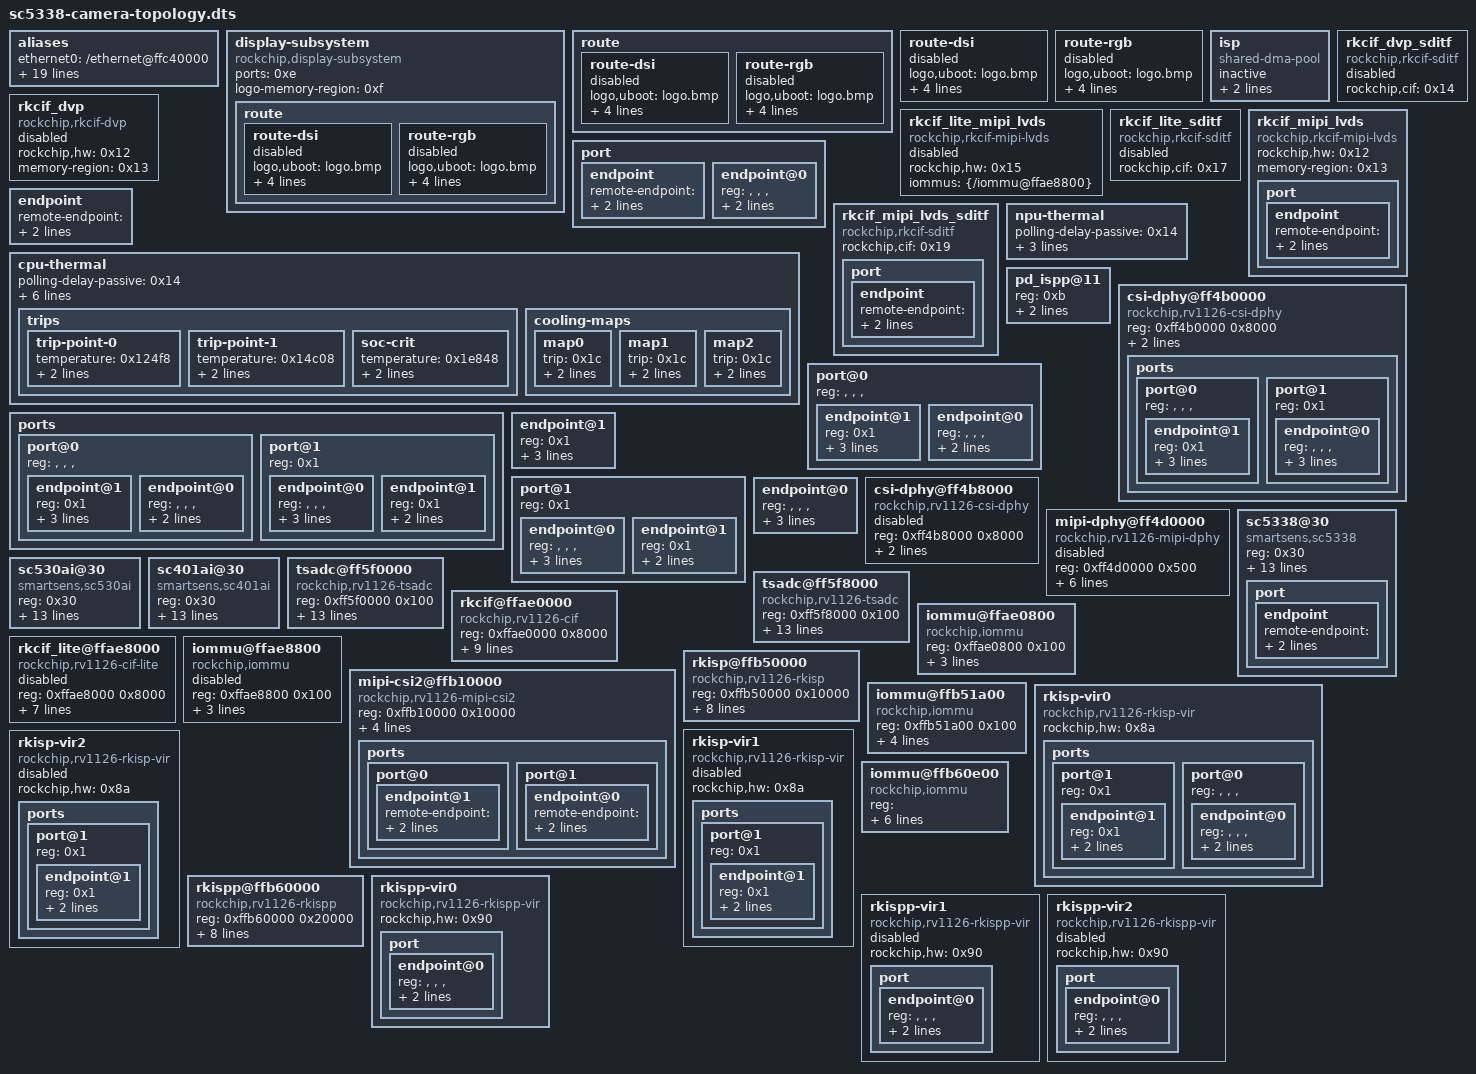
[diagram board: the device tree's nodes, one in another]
/* SC5338 摄像头链路节点摘录 —— 来源 docs/evidence/vendor-kernel.dtb
   DTB 85937 B / md5 2e96cb2dd8321c19425b73490586bb01
   共 441 个节点，命中 72 个摄像头相关节点。
   每个片段前的注释是节点在 DTB 里的完整路径，片段本身可直接抄进目标 DTS。 */

/* /aliases */
aliases {
	ethernet0 = "/ethernet@ffc40000";
	i2c0 = "/i2c@ff3f0000";
	i2c1 = "/i2c@ff510000";
	i2c2 = "/i2c@ff400000";
	i2c3 = "/i2c@ff520000";
	i2c4 = "/i2c@ff530000";
	i2c5 = "/i2c@ff540000";
	mmc0 = "/dwmmc@ffc50000";
	mmc1 = "/dwmmc@ffc70000";
	mmc2 = "/dwmmc@ffc60000";
	serial0 = "/serial@ff560000";
	serial1 = "/serial@ff410000";
	serial2 = "/serial@ff570000";
	serial3 = "/serial@ff580000";
	serial4 = "/serial@ff590000";
	serial5 = "/serial@ff5a0000";
	spi0 = "/spi@ff450000";
	spi1 = "/spi@ff5b0000";
	dphy0 = "/csi-dphy@ff4b0000";
	dphy1 = "/csi-dphy@ff4b8000";
};

/* /display-subsystem */
display-subsystem {
	compatible = "rockchip,display-subsystem";
	ports = <0xe>;
	status = "okay";
	logo-memory-region = <0xf>;
	phandle = <0xc7>;
	route {
		route-dsi {
			status = "disabled";
			logo,uboot = "logo.bmp";
			logo,kernel = "logo_kernel.bmp";
			logo,mode = "center";
			charge_logo,mode = "center";
			connect = <0x10>;
			phandle = <0xc8>;
		};
		route-rgb {
			status = "disabled";
			logo,uboot = "logo.bmp";
			logo,kernel = "logo_kernel.bmp";
			logo,mode = "center";
			charge_logo,mode = "center";
			connect = <0x11>;
			phandle = <0xc9>;
		};
	};
};

/* /display-subsystem/route */
route {
	route-dsi {
		status = "disabled";
		logo,uboot = "logo.bmp";
		logo,kernel = "logo_kernel.bmp";
		logo,mode = "center";
		charge_logo,mode = "center";
		connect = <0x10>;
		phandle = <0xc8>;
	};
	route-rgb {
		status = "disabled";
		logo,uboot = "logo.bmp";
		logo,kernel = "logo_kernel.bmp";
		logo,mode = "center";
		charge_logo,mode = "center";
		connect = <0x11>;
		phandle = <0xc9>;
	};
};

/* /display-subsystem/route/route-dsi */
route-dsi {
	status = "disabled";
	logo,uboot = "logo.bmp";
	logo,kernel = "logo_kernel.bmp";
	logo,mode = "center";
	charge_logo,mode = "center";
	connect = <0x10>;
	phandle = <0xc8>;
};

/* /display-subsystem/route/route-rgb */
route-rgb {
	status = "disabled";
	logo,uboot = "logo.bmp";
	logo,kernel = "logo_kernel.bmp";
	logo,mode = "center";
	charge_logo,mode = "center";
	connect = <0x11>;
	phandle = <0xc9>;
};

/* /reserved-memory/isp */
isp {
	compatible = "shared-dma-pool";
	inactive;
	reusable;
	size = "", "", "", "";
	phandle = <0x13>;
};

/* /rkcif_dvp */
rkcif_dvp {
	compatible = "rockchip,rkcif-dvp";
	rockchip,hw = <0x12>;
	memory-region = <0x13>;
	status = "disabled";
	phandle = <0x14>;
};

/* /rkcif_dvp_sditf */
rkcif_dvp_sditf {
	compatible = "rockchip,rkcif-sditf";
	rockchip,cif = <0x14>;
	status = "disabled";
	phandle = <0xcd>;
};

/* /rkcif_lite_mipi_lvds */
rkcif_lite_mipi_lvds {
	compatible = "rockchip,rkcif-mipi-lvds";
	rockchip,hw = <0x15>;
	iommus = <&{/iommu@ffae8800}>;
	status = "disabled";
	phandle = <0x17>;
};

/* /rkcif_lite_sditf */
rkcif_lite_sditf {
	compatible = "rockchip,rkcif-sditf";
	rockchip,cif = <0x17>;
	status = "disabled";
	phandle = <0xce>;
};

/* /rkcif_mipi_lvds */
rkcif_mipi_lvds {
	compatible = "rockchip,rkcif-mipi-lvds";
	rockchip,hw = <0x12>;
	memory-region = <0x13>;
	status = "okay";
	phandle = <0x19>;
	port {
		endpoint {
			remote-endpoint = <&{/mipi-csi2@ffb10000/ports/port@1/endpoint@0}>;
			data-lanes = <0x1 0x2>;
			phandle = <0x85>;
		};
	};
};

/* /rkcif_mipi_lvds/port */
port {
	endpoint {
		remote-endpoint = <&{/mipi-csi2@ffb10000/ports/port@1/endpoint@0}>;
		data-lanes = <0x1 0x2>;
		phandle = <0x85>;
	};
};

/* /rkcif_mipi_lvds/port/endpoint */
endpoint {
	remote-endpoint = <&{/mipi-csi2@ffb10000/ports/port@1/endpoint@0}>;
	data-lanes = <0x1 0x2>;
	phandle = <0x85>;
};

/* /rkcif_mipi_lvds_sditf */
rkcif_mipi_lvds_sditf {
	compatible = "rockchip,rkcif-sditf";
	rockchip,cif = <0x19>;
	status = "okay";
	phandle = <0xcf>;
	port {
		endpoint {
			remote-endpoint = <&{/rkisp-vir0/ports/port@0/endpoint@0}>;
			data-lanes = <0x1 0x2>;
			phandle = <0x8c>;
		};
	};
};

/* /rkcif_mipi_lvds_sditf/port */
port {
	endpoint {
		remote-endpoint = <&{/rkisp-vir0/ports/port@0/endpoint@0}>;
		data-lanes = <0x1 0x2>;
		phandle = <0x8c>;
	};
};

/* /rkcif_mipi_lvds_sditf/port/endpoint */
endpoint {
	remote-endpoint = <&{/rkisp-vir0/ports/port@0/endpoint@0}>;
	data-lanes = <0x1 0x2>;
	phandle = <0x8c>;
};

/* /thermal-zones/cpu-thermal */
cpu-thermal {
	polling-delay-passive = <0x14>;
	polling-delay = <0x3e8>;
	sustainable-power = <0x36b>;
	k_pu = <0x4b>;
	k_po = <0xaf>;
	k_i = "", "", "", "";
	thermal-sensors = <0x1b 0x0>;
	phandle = <0xd3>;
	trips {
		trip-point-0 {
			temperature = <0x124f8>;
			hysteresis = <0x7d0>;
			type = "passive";
			phandle = <0xd4>;
		};
		trip-point-1 {
			temperature = <0x14c08>;
			hysteresis = <0x7d0>;
			type = "passive";
			phandle = <0x1c>;
		};
		soc-crit {
			temperature = <0x1e848>;
			hysteresis = <0x7d0>;
			type = "critical";
			phandle = <0xd5>;
		};
	};
	cooling-maps {
		map0 {
			trip = <0x1c>;
			cooling-device = <0xa 0xffffffff 0xffffffff>;
			contribution = <0x400>;
		};
		map1 {
			trip = <0x1c>;
			cooling-device = <0x1d 0xffffffff 0xffffffff>;
			contribution = <0x400>;
		};
		map2 {
			trip = <0x1c>;
			cooling-device = <0x1e 0xffffffff 0xffffffff>;
			contribution = <0x424>;
		};
	};
};

/* /thermal-zones/npu-thermal */
npu-thermal {
	polling-delay-passive = <0x14>;
	polling-delay = <0x3e8>;
	sustainable-power = <0x3d1>;
	thermal-sensors = <0x1f 0x0>;
	phandle = <0xd6>;
};

/* /power-management@ff3e0000/power-controller/pd_ispp@11 */
pd_ispp@11 {
	reg = <0xb>;
	clocks = <0x2 0xba 0x2 0xe1 0x2 0x6b>;  /* 0x2->&{/clock-controller@ff490000}, 0xba->&{/pinctrl/pcfg-output-low}, 0x2->&{/clock-controller@ff490000}, 0xe1->&{/pwm@ff430000}, 0x2->&{/clock-controller@ff490000}, 0x6b->&{/otp@ff5c0000/tsadc-trim-base@27} */
	pm_qos = <0x2e 0x2f>;
};

/* /csi-dphy@ff4b0000 */
csi-dphy@ff4b0000 {
	compatible = "rockchip,rv1126-csi-dphy";
	reg = <0xff4b0000 0x8000>;
	clocks = <0x2 0x122>;  /* 0x2->&{/clock-controller@ff490000}, 0x122->&{/usb0/dwc3@ffd00000} */
	clock-names = "pclk";
	rockchip,grf = <0x48>;
	status = "okay";
	phandle = <0xea>;
	ports {
		#address-cells = <0x1>;
		#size-cells = "", "", "", "";
		port@0 {
			reg = "", "", "", "";
			#address-cells = <0x1>;
			#size-cells = "", "", "", "";
			endpoint@1 {
				reg = <0x1>;
				remote-endpoint = <&{/i2c@ff510000/sc5338@30/port/endpoint}>;
				data-lanes = <0x1 0x2>;
				phandle = <0x52>;
			};
		};
		port@1 {
			reg = <0x1>;
			#address-cells = <0x1>;
			#size-cells = "", "", "", "";
			endpoint@0 {
				reg = "", "", "", "";
				remote-endpoint = <&{/mipi-csi2@ffb10000/ports/port@0/endpoint@1}>;
				data-lanes = <0x1 0x2>;
				phandle = <0x84>;
			};
		};
	};
};

/* /csi-dphy@ff4b0000/ports */
ports {
	#address-cells = <0x1>;
	#size-cells = "", "", "", "";
	port@0 {
		reg = "", "", "", "";
		#address-cells = <0x1>;
		#size-cells = "", "", "", "";
		endpoint@1 {
			reg = <0x1>;
			remote-endpoint = <&{/i2c@ff510000/sc5338@30/port/endpoint}>;
			data-lanes = <0x1 0x2>;
			phandle = <0x52>;
		};
	};
	port@1 {
		reg = <0x1>;
		#address-cells = <0x1>;
		#size-cells = "", "", "", "";
		endpoint@0 {
			reg = "", "", "", "";
			remote-endpoint = <&{/mipi-csi2@ffb10000/ports/port@0/endpoint@1}>;
			data-lanes = <0x1 0x2>;
			phandle = <0x84>;
		};
	};
};

/* /csi-dphy@ff4b0000/ports/port@0 */
port@0 {
	reg = "", "", "", "";
	#address-cells = <0x1>;
	#size-cells = "", "", "", "";
	endpoint@1 {
		reg = <0x1>;
		remote-endpoint = <&{/i2c@ff510000/sc5338@30/port/endpoint}>;
		data-lanes = <0x1 0x2>;
		phandle = <0x52>;
	};
};

/* /csi-dphy@ff4b0000/ports/port@0/endpoint@1 */
endpoint@1 {
	reg = <0x1>;
	remote-endpoint = <&{/i2c@ff510000/sc5338@30/port/endpoint}>;
	data-lanes = <0x1 0x2>;
	phandle = <0x52>;
};

/* /csi-dphy@ff4b0000/ports/port@1 */
port@1 {
	reg = <0x1>;
	#address-cells = <0x1>;
	#size-cells = "", "", "", "";
	endpoint@0 {
		reg = "", "", "", "";
		remote-endpoint = <&{/mipi-csi2@ffb10000/ports/port@0/endpoint@1}>;
		data-lanes = <0x1 0x2>;
		phandle = <0x84>;
	};
};

/* /csi-dphy@ff4b0000/ports/port@1/endpoint@0 */
endpoint@0 {
	reg = "", "", "", "";
	remote-endpoint = <&{/mipi-csi2@ffb10000/ports/port@0/endpoint@1}>;
	data-lanes = <0x1 0x2>;
	phandle = <0x84>;
};

/* /csi-dphy@ff4b8000 */
csi-dphy@ff4b8000 {
	compatible = "rockchip,rv1126-csi-dphy";
	reg = <0xff4b8000 0x8000>;
	clocks = <0x2 0x123>;  /* 0x2->&{/clock-controller@ff490000}, 0x123->&{/usb@ffe00000} */
	clock-names = "pclk";
	rockchip,grf = <0x48>;
	status = "disabled";
	phandle = <0xeb>;
};

/* /mipi-dphy@ff4d0000 */
mipi-dphy@ff4d0000 {
	compatible = "rockchip,rv1126-mipi-dphy", "rockchip,rk1808-mipi-dphy";
	reg = <0xff4d0000 0x500>;
	assigned-clocks = <0x38 0x1a>;  /* 0x38->&{/clock-controller@ff480000}, 0x1a->&{/rkisp-vir0/ports/port@0/endpoint@0} */
	assigned-clock-rates = <0x16e3600>;
	clocks = <0x38 0x1a 0x2 0x121>;  /* 0x38->&{/clock-controller@ff480000}, 0x1a->&{/rkisp-vir0/ports/port@0/endpoint@0}, 0x2->&{/clock-controller@ff490000}, 0x121->&{/usb0} */
	clock-names = "ref", "pclk";
	clock-output-names = "mipi_dphy_pll";
	#clock-cells = "", "", "", "";
	resets = <0x2 0xe6>;  /* 0x2->&{/clock-controller@ff490000}, 0xe6->&{/pwm@ff440010} */
	reset-names = "apb";
	#phy-cells = "", "", "", "";
	rockchip,grf = <0x48>;
	status = "disabled";
	phandle = <0x88>;
};

/* /i2c@ff510000/sc5338@30 */
sc5338@30 {
	compatible = "smartsens,sc5338";
	reg = <0x30>;
	clocks = <0x2 0x67>;  /* 0x2->&{/clock-controller@ff490000}, 0x67->&{/pinctrl/spi1/spi1m0-pins} */
	clock-names = "xvclk";
	power-domains = <0x4d 0x9>;  /* 0x4d->&{/power-management@ff3e0000/power-controller}, 0x9->&{/otp@ff5c0000/cpu-code@2} */
	pinctrl-names = "rockchip,camera_default";
	pinctrl-0 = <&{/pinctrl/mipicsi/mipicsi-clk0}>;
	avdd-supply = <&{/vcc33sys}>;
	dovdd-supply = <&{/vcc-1v8}>;
	dvdd-supply = <&{/vcc-dvdd}>;
	pwdn-gpios = <0x51 0x1c 0x0>;
	reset-gpios = <0x51 0x1d 0x0>;
	rockchip,camera-module-index = <0x1>;
	rockchip,camera-module-facing = "front";
	rockchip,camera-module-name = "CMK-OT1607-FV1";
	rockchip,camera-module-lens-name = "M12-40IRC-4MP-F16";
	phandle = <0xef>;
	port {
		endpoint {
			remote-endpoint = <&{/csi-dphy@ff4b0000/ports/port@0/endpoint@1}>;
			data-lanes = <0x1 0x2>;
			phandle = <0x49>;
		};
	};
};

/* /i2c@ff510000/sc5338@30/port */
port {
	endpoint {
		remote-endpoint = <&{/csi-dphy@ff4b0000/ports/port@0/endpoint@1}>;
		data-lanes = <0x1 0x2>;
		phandle = <0x49>;
	};
};

/* /i2c@ff510000/sc5338@30/port/endpoint */
endpoint {
	remote-endpoint = <&{/csi-dphy@ff4b0000/ports/port@0/endpoint@1}>;
	data-lanes = <0x1 0x2>;
	phandle = <0x49>;
};

/* /i2c@ff510000/sc530ai@30 */
sc530ai@30 {
	compatible = "smartsens,sc530ai";
	reg = <0x30>;
	clocks = <0x2 0x67>;  /* 0x2->&{/clock-controller@ff490000}, 0x67->&{/pinctrl/spi1/spi1m0-pins} */
	clock-names = "xvclk";
	power-domains = <0x4d 0x9>;  /* 0x4d->&{/power-management@ff3e0000/power-controller}, 0x9->&{/otp@ff5c0000/cpu-code@2} */
	pinctrl-names = "rockchip,camera_default";
	pinctrl-0 = <&{/pinctrl/mipicsi/mipicsi-clk0}>;
	avdd-supply = <&{/vcc33sys}>;
	dovdd-supply = <&{/vcc-1v8}>;
	dvdd-supply = <&{/vcc-dvdd}>;
	pwdn-gpios = <0x51 0x1c 0x0>;
	reset-gpios = <0x51 0x1d 0x0>;
	rockchip,camera-module-index = <0x1>;
	rockchip,camera-module-facing = "front";
	rockchip,camera-module-name = "CMK-OT1607-FV1";
	rockchip,camera-module-lens-name = "M12-40IRC-4MP-F16";
	phandle = <0xf0>;
};

/* /i2c@ff510000/sc401ai@30 */
sc401ai@30 {
	compatible = "smartsens,sc401ai";
	reg = <0x30>;
	clocks = <0x2 0x67>;  /* 0x2->&{/clock-controller@ff490000}, 0x67->&{/pinctrl/spi1/spi1m0-pins} */
	clock-names = "xvclk";
	power-domains = <0x4d 0x9>;  /* 0x4d->&{/power-management@ff3e0000/power-controller}, 0x9->&{/otp@ff5c0000/cpu-code@2} */
	pinctrl-names = "rockchip,camera_default";
	pinctrl-0 = <&{/pinctrl/mipicsi/mipicsi-clk0}>;
	avdd-supply = <&{/vcc33sys}>;
	dovdd-supply = <&{/vcc-1v8}>;
	dvdd-supply = <&{/vcc-dvdd}>;
	pwdn-gpios = <0x51 0x1c 0x0>;
	reset-gpios = <0x51 0x1d 0x0>;
	rockchip,camera-module-index = <0x1>;
	rockchip,camera-module-facing = "front";
	rockchip,camera-module-name = "CMK-OT1607-FV1";
	rockchip,camera-module-lens-name = "M12-40IRC-4MP-F16";
	phandle = <0xf1>;
};

/* /tsadc@ff5f0000 */
tsadc@ff5f0000 {
	compatible = "rockchip,rv1126-tsadc";
	reg = <0xff5f0000 0x100>;
	rockchip,grf = <0x48>;
	interrupts = <0x0 0x27 0x4>;
	assigned-clocks = <0x2 0x36>;  /* 0x2->&{/clock-controller@ff490000}, 0x36->&{/qos@fe810000} */
	assigned-clock-rates = <0x3d0900>;
	clocks = <0x2 0x36 0x2 0x10f 0x2 0x37>;  /* 0x2->&{/clock-controller@ff490000}, 0x36->&{/qos@fe810000}, 0x2->&{/clock-controller@ff490000}, 0x10f->&{/iep@ffb20000}, 0x2->&{/clock-controller@ff490000}, 0x37->&{/qos@fe810080} */
	clock-names = "tsadc", "apb_pclk", "phy_clk";
	resets = <0x2 0xe8 0x2 0xe9 0x2 0xea>;  /* 0x2->&{/clock-controller@ff490000}, 0xe8->&{/pwm@ff440030}, 0x2->&{/clock-controller@ff490000}, 0xe9->&{/spi@ff450000}, 0x2->&{/clock-controller@ff490000}, 0xea->&{/csi-dphy@ff4b0000} */
	reset-names = "tsadc-apb", "tsadc", "tsadc-phy";
	rockchip,hw-tshut-temp = <0x1d4c0>;
	#thermal-sensor-cells = <0x1>;
	nvmem-cells = <0x69 0x6a 0x6b>;
	nvmem-cell-names = "trim_l", "trim_h", "trim_base";
	rockchip,hw-tshut-mode = "", "", "", "";
	rockchip,hw-tshut-polarity = "", "", "", "";
	pinctrl-names = "gpio", "otpout";
	pinctrl-0 = <&{/pinctrl/tsadc/tsadcm0-shut}>;
	pinctrl-1 = <&{/pinctrl/tsadc/tsadc-shutorg}>;
	status = "okay";
	phandle = <0x1b>;
};

/* /tsadc@ff5f8000 */
tsadc@ff5f8000 {
	compatible = "rockchip,rv1126-tsadc";
	reg = <0xff5f8000 0x100>;
	rockchip,grf = <0x48>;
	interrupts = <0x0 0x71 0x4>;
	assigned-clocks = <0x2 0x34>;  /* 0x2->&{/clock-controller@ff490000}, 0x34->&{/qos@fe860200} */
	assigned-clock-rates = <0x3d0900>;
	clocks = <0x2 0x34 0x2 0x10e 0x2 0x35>;  /* 0x2->&{/clock-controller@ff490000}, 0x34->&{/qos@fe860200}, 0x2->&{/clock-controller@ff490000}, 0x10e->&{/mipi-csi2@ffb10000}, 0x2->&{/clock-controller@ff490000}, 0x35->&{/qos@fe86c000} */
	clock-names = "tsadc", "apb_pclk", "phy_clk";
	resets = <0x2 0xd8 0x2 0xd9 0x2 0xda>;  /* 0x2->&{/clock-controller@ff490000}, 0xd8->&{/dummy_cpll}, 0x2->&{/clock-controller@ff490000}, 0xd9->&{/external-gmac-clockm0}, 0x2->&{/clock-controller@ff490000}, 0xda->&{/external-gmac-clockm1} */
	reset-names = "tsadc-apb", "tsadc", "tsadc-phy";
	rockchip,hw-tshut-temp = <0x1d4c0>;
	#thermal-sensor-cells = <0x1>;
	nvmem-cells = <0x6e 0x6f 0x6b>;
	nvmem-cell-names = "trim_l", "trim_h", "trim_base";
	rockchip,hw-tshut-mode = "", "", "", "";
	rockchip,hw-tshut-polarity = "", "", "", "";
	pinctrl-names = "gpio", "otpout";
	pinctrl-0 = <&{/pinctrl/tsadc/tsadcm0-shut}>;
	pinctrl-1 = <&{/pinctrl/tsadc/tsadc-shutorg}>;
	status = "okay";
	phandle = <0x1f>;
};

/* /rkcif@ffae0000 */
rkcif@ffae0000 {
	compatible = "rockchip,rv1126-cif";
	reg = <0xffae0000 0x8000>;
	reg-names = "cif_regs";
	interrupts = <0x0 0x3a 0x4>;
	interrupt-names = "cif-intr";
	clocks = <0x2 0xb5 0x2 0xde 0x2 0x9b>;  /* 0x2->&{/clock-controller@ff490000}, 0xb5->&{/pinctrl/pcfg-pull-up}, 0x2->&{/clock-controller@ff490000}, 0xde->&{/i2c@ff3f0000}, 0x2->&{/clock-controller@ff490000}, 0x9b->&{/ethernet@ffc40000/rx-queues-config} */
	clock-names = "aclk_cif", "hclk_cif", "dclk_cif";
	resets = <0x2 0x94 0x2 0x95 0x2 0x96 0x2 0x97 0x2 0x98 0x2 0x99>;  /* 0x2->&{/clock-controller@ff490000}, 0x94->&{/iommu@ffb80480}, 0x2->&{/clock-controller@ff490000}, 0x95->&{/iommu@ffb90800}, 0x2->&{/clock-controller@ff490000}, 0x96->&{/rkvenc-opp-table}, 0x2->&{/clock-controller@ff490000}, 0x97->&{/iommu@ffbb0f00}, 0x2->&{/clock-controller@ff490000}, 0x98->&{/otp@ff5c0000/venc-leakage@1a}, 0x2->&{/clock-controller@ff490000}, 0x99->&{/otp@ff5c0000/venc-performance@1f} */
	reset-names = "rst_cif_a", "rst_cif_h", "rst_cif_d", "rst_cif_p", "rst_cif_i", "rst_cif_rx_p";
	assigned-clocks = <0x2 0x9b>;  /* 0x2->&{/clock-controller@ff490000}, 0x9b->&{/ethernet@ffc40000/rx-queues-config} */
	assigned-clock-rates = <0x11e1a300>;
	power-domains = <0x4d 0x9>;  /* 0x4d->&{/power-management@ff3e0000/power-controller}, 0x9->&{/otp@ff5c0000/cpu-code@2} */
	rockchip,grf = <0x48>;
	status = "okay";
	iommus = <&{/iommu@ffae0800}>;
	phandle = <0x12>;
};

/* /iommu@ffae0800 */
iommu@ffae0800 {
	compatible = "rockchip,iommu";
	reg = <0xffae0800 0x100>;
	interrupts = <0x0 0x3a 0x4>;
	interrupt-names = "cif_mmu";
	clocks = <0x2 0xb5 0x2 0xde>;  /* 0x2->&{/clock-controller@ff490000}, 0xb5->&{/pinctrl/pcfg-pull-up}, 0x2->&{/clock-controller@ff490000}, 0xde->&{/i2c@ff3f0000} */
	clock-names = "aclk", "iface";
	power-domains = <0x4d 0x9>;  /* 0x4d->&{/power-management@ff3e0000/power-controller}, 0x9->&{/otp@ff5c0000/cpu-code@2} */
	#iommu-cells = "", "", "", "";
	status = "okay";
	phandle = <0x80>;
};

/* /rkcif_lite@ffae8000 */
rkcif_lite@ffae8000 {
	compatible = "rockchip,rv1126-cif-lite";
	reg = <0xffae8000 0x8000>;
	reg-names = "cif_regs";
	interrupts = <0x0 0x35 0x4>;
	interrupt-names = "cif-lite-intr";
	clocks = <0x2 0xb6 0x2 0xdf 0x2 0x9c>;  /* 0x2->&{/clock-controller@ff490000}, 0xb6->&{/pinctrl/pcfg-pull-down}, 0x2->&{/clock-controller@ff490000}, 0xdf->&{/i2c@ff400000}, 0x2->&{/clock-controller@ff490000}, 0x9c->&{/ethernet@ffc40000/tx-queues-config} */
	clock-names = "aclk_cif_lite", "hclk_cif_lite", "dclk_cif_lite";
	resets = <0x2 0xdc 0x2 0xdd 0x2 0xde 0x2 0xdf>;  /* 0x2->&{/clock-controller@ff490000}, 0xdc->&{/syscon@fe020000/io-domains}, 0x2->&{/clock-controller@ff490000}, 0xdd->&{/power-management@ff3e0000}, 0x2->&{/clock-controller@ff490000}, 0xde->&{/i2c@ff3f0000}, 0x2->&{/clock-controller@ff490000}, 0xdf->&{/i2c@ff400000} */
	reset-names = "rst_cif_lite_a", "rst_cif_lite_h", "rst_cif_lite_d", "rst_cif_lite_rx_p";
	assigned-clocks = <0x2 0x9c>;  /* 0x2->&{/clock-controller@ff490000}, 0x9c->&{/ethernet@ffc40000/tx-queues-config} */
	assigned-clock-rates = <0x11e1a300>;
	power-domains = <0x4d 0x9>;  /* 0x4d->&{/power-management@ff3e0000/power-controller}, 0x9->&{/otp@ff5c0000/cpu-code@2} */
	iommus = <&{/iommu@ffae8800}>;
	status = "disabled";
	phandle = <0x15>;
};

/* /iommu@ffae8800 */
iommu@ffae8800 {
	compatible = "rockchip,iommu";
	reg = <0xffae8800 0x100>;
	interrupts = <0x0 0x35 0x4>;
	interrupt-names = "cif_lite_mmu";
	clocks = <0x2 0xb6 0x2 0xdf>;  /* 0x2->&{/clock-controller@ff490000}, 0xb6->&{/pinctrl/pcfg-pull-down}, 0x2->&{/clock-controller@ff490000}, 0xdf->&{/i2c@ff400000} */
	clock-names = "aclk", "iface";
	power-domains = <0x4d 0x9>;  /* 0x4d->&{/power-management@ff3e0000/power-controller}, 0x9->&{/otp@ff5c0000/cpu-code@2} */
	#iommu-cells = "", "", "", "";
	status = "disabled";
	phandle = <0x16>;
};

/* /mipi-csi2@ffb10000 */
mipi-csi2@ffb10000 {
	compatible = "rockchip,rv1126-mipi-csi2";
	reg = <0xffb10000 0x10000>;
	reg-names = "csihost_regs";
	interrupts = <0x0 0x38 0x4 0x0 0x39 0x4>;
	interrupt-names = "csi-intr1", "csi-intr2";
	clocks = <0x2 0x114>;  /* 0x2->&{/clock-controller@ff490000}, 0x114->&{/rkispp-vir0} */
	clock-names = "pclk_csi2host";
	resets = <0x2 0x9f>;  /* 0x2->&{/clock-controller@ff490000}, 0x9f->&{/pinctrl/rmii/rmiim0-bus2} */
	reset-names = "srst_csihost_p";
	power-domains = <0x4d 0x9>;  /* 0x4d->&{/power-management@ff3e0000/power-controller}, 0x9->&{/otp@ff5c0000/cpu-code@2} */
	status = "okay";
	phandle = <0x10e>;
	ports {
		port@0 {
			endpoint@1 {
				remote-endpoint = <&{/csi-dphy@ff4b0000/ports/port@1/endpoint@0}>;
				data-lanes = <0x1 0x2>;
				phandle = <0x4a>;
			};
		};
		port@1 {
			endpoint@0 {
				remote-endpoint = <&{/rkcif_mipi_lvds/port/endpoint}>;
				data-lanes = <0x1 0x2>;
				phandle = <0x18>;
			};
		};
	};
};

/* /mipi-csi2@ffb10000/ports */
ports {
	port@0 {
		endpoint@1 {
			remote-endpoint = <&{/csi-dphy@ff4b0000/ports/port@1/endpoint@0}>;
			data-lanes = <0x1 0x2>;
			phandle = <0x4a>;
		};
	};
	port@1 {
		endpoint@0 {
			remote-endpoint = <&{/rkcif_mipi_lvds/port/endpoint}>;
			data-lanes = <0x1 0x2>;
			phandle = <0x18>;
		};
	};
};

/* /mipi-csi2@ffb10000/ports/port@0 */
port@0 {
	endpoint@1 {
		remote-endpoint = <&{/csi-dphy@ff4b0000/ports/port@1/endpoint@0}>;
		data-lanes = <0x1 0x2>;
		phandle = <0x4a>;
	};
};

/* /mipi-csi2@ffb10000/ports/port@0/endpoint@1 */
endpoint@1 {
	remote-endpoint = <&{/csi-dphy@ff4b0000/ports/port@1/endpoint@0}>;
	data-lanes = <0x1 0x2>;
	phandle = <0x4a>;
};

/* /mipi-csi2@ffb10000/ports/port@1 */
port@1 {
	endpoint@0 {
		remote-endpoint = <&{/rkcif_mipi_lvds/port/endpoint}>;
		data-lanes = <0x1 0x2>;
		phandle = <0x18>;
	};
};

/* /mipi-csi2@ffb10000/ports/port@1/endpoint@0 */
endpoint@0 {
	remote-endpoint = <&{/rkcif_mipi_lvds/port/endpoint}>;
	data-lanes = <0x1 0x2>;
	phandle = <0x18>;
};

/* /rkisp@ffb50000 */
rkisp@ffb50000 {
	compatible = "rockchip,rv1126-rkisp";
	reg = <0xffb50000 0x10000>;
	interrupts = <0x0 0x34 0x4 0x0 0x36 0x4 0x0 0x37 0x4>;
	interrupt-names = "isp_irq", "mi_irq", "mipi_irq";
	clocks = <0x2 0xb4 0x2 0xdd 0x2 0x5f>;  /* 0x2->&{/clock-controller@ff490000}, 0xb4->&{/pinctrl/pcfg-pull-up-drv-level-2}, 0x2->&{/clock-controller@ff490000}, 0xdd->&{/power-management@ff3e0000}, 0x2->&{/clock-controller@ff490000}, 0x5f->&{/pinctrl/uart4/uart4m0-xfer} */
	clock-names = "aclk_isp", "hclk_isp", "clk_isp";
	assigned-clocks = <0x2 0xb4 0x2 0xdd>;  /* 0x2->&{/clock-controller@ff490000}, 0xb4->&{/pinctrl/pcfg-pull-up-drv-level-2}, 0x2->&{/clock-controller@ff490000}, 0xdd->&{/power-management@ff3e0000} */
	assigned-clock-rates = <0x1dcd6500 0xee6b280>;
	resets = <0x2 0x93 0x2 0x8e>;  /* 0x2->&{/clock-controller@ff490000}, 0x93->&{/rkisp-vir2/ports/port@1/endpoint@1}, 0x2->&{/clock-controller@ff490000}, 0x8e->&{/rkispp-vir2/port/endpoint@0} */
	reset-names = "isp", "isp-rx-p";
	power-domains = <0x4d 0x9>;  /* 0x4d->&{/power-management@ff3e0000/power-controller}, 0x9->&{/otp@ff5c0000/cpu-code@2} */
	iommus = <&{/iommu@ffb51a00}>;
	status = "okay";
	phandle = <0x8a>;
};

/* /iommu@ffb51a00 */
iommu@ffb51a00 {
	compatible = "rockchip,iommu";
	reg = <0xffb51a00 0x100>;
	interrupts = <0x0 0x33 0x4>;
	interrupt-names = "isp_mmu";
	clocks = <0x2 0xb4 0x2 0xdd>;  /* 0x2->&{/clock-controller@ff490000}, 0xb4->&{/pinctrl/pcfg-pull-up-drv-level-2}, 0x2->&{/clock-controller@ff490000}, 0xdd->&{/power-management@ff3e0000} */
	clock-names = "aclk", "iface";
	power-domains = <0x4d 0x9>;  /* 0x4d->&{/power-management@ff3e0000/power-controller}, 0x9->&{/otp@ff5c0000/cpu-code@2} */
	#iommu-cells = "", "", "", "";
	rockchip,disable-mmu-reset;
	status = "okay";
	phandle = <0x89>;
};

/* /rkisp-vir0 */
rkisp-vir0 {
	compatible = "rockchip,rv1126-rkisp-vir";
	rockchip,hw = <0x8a>;
	status = "okay";
	phandle = <0x111>;
	ports {
		#address-cells = <0x1>;
		#size-cells = "", "", "", "";
		port@1 {
			reg = <0x1>;
			#address-cells = <0x1>;
			#size-cells = "", "", "", "";
			endpoint@1 {
				reg = <0x1>;
				remote-endpoint = <&{/rkispp-vir0/port/endpoint@0}>;
				phandle = <0x91>;
			};
		};
		port@0 {
			reg = "", "", "", "";
			#address-cells = <0x1>;
			#size-cells = "", "", "", "";
			endpoint@0 {
				reg = "", "", "", "";
				remote-endpoint = <&{/rkcif_mipi_lvds_sditf/port/endpoint}>;
				phandle = <0x1a>;
			};
		};
	};
};

/* /rkisp-vir0/ports */
ports {
	#address-cells = <0x1>;
	#size-cells = "", "", "", "";
	port@1 {
		reg = <0x1>;
		#address-cells = <0x1>;
		#size-cells = "", "", "", "";
		endpoint@1 {
			reg = <0x1>;
			remote-endpoint = <&{/rkispp-vir0/port/endpoint@0}>;
			phandle = <0x91>;
		};
	};
	port@0 {
		reg = "", "", "", "";
		#address-cells = <0x1>;
		#size-cells = "", "", "", "";
		endpoint@0 {
			reg = "", "", "", "";
			remote-endpoint = <&{/rkcif_mipi_lvds_sditf/port/endpoint}>;
			phandle = <0x1a>;
		};
	};
};

/* /rkisp-vir0/ports/port@1 */
port@1 {
	reg = <0x1>;
	#address-cells = <0x1>;
	#size-cells = "", "", "", "";
	endpoint@1 {
		reg = <0x1>;
		remote-endpoint = <&{/rkispp-vir0/port/endpoint@0}>;
		phandle = <0x91>;
	};
};

/* /rkisp-vir0/ports/port@1/endpoint@1 */
endpoint@1 {
	reg = <0x1>;
	remote-endpoint = <&{/rkispp-vir0/port/endpoint@0}>;
	phandle = <0x91>;
};

/* /rkisp-vir0/ports/port@0 */
port@0 {
	reg = "", "", "", "";
	#address-cells = <0x1>;
	#size-cells = "", "", "", "";
	endpoint@0 {
		reg = "", "", "", "";
		remote-endpoint = <&{/rkcif_mipi_lvds_sditf/port/endpoint}>;
		phandle = <0x1a>;
	};
};

/* /rkisp-vir0/ports/port@0/endpoint@0 */
endpoint@0 {
	reg = "", "", "", "";
	remote-endpoint = <&{/rkcif_mipi_lvds_sditf/port/endpoint}>;
	phandle = <0x1a>;
};

/* /rkisp-vir1 */
rkisp-vir1 {
	compatible = "rockchip,rv1126-rkisp-vir";
	rockchip,hw = <0x8a>;
	status = "disabled";
	phandle = <0x112>;
	ports {
		#address-cells = <0x1>;
		#size-cells = "", "", "", "";
		port@1 {
			reg = <0x1>;
			#address-cells = <0x1>;
			#size-cells = "", "", "", "";
			endpoint@1 {
				reg = <0x1>;
				remote-endpoint = <&{/rkispp-vir1/port/endpoint@0}>;
				phandle = <0x92>;
			};
		};
	};
};

/* /rkisp-vir1/ports */
ports {
	#address-cells = <0x1>;
	#size-cells = "", "", "", "";
	port@1 {
		reg = <0x1>;
		#address-cells = <0x1>;
		#size-cells = "", "", "", "";
		endpoint@1 {
			reg = <0x1>;
			remote-endpoint = <&{/rkispp-vir1/port/endpoint@0}>;
			phandle = <0x92>;
		};
	};
};

/* /rkisp-vir1/ports/port@1 */
port@1 {
	reg = <0x1>;
	#address-cells = <0x1>;
	#size-cells = "", "", "", "";
	endpoint@1 {
		reg = <0x1>;
		remote-endpoint = <&{/rkispp-vir1/port/endpoint@0}>;
		phandle = <0x92>;
	};
};

/* /rkisp-vir1/ports/port@1/endpoint@1 */
endpoint@1 {
	reg = <0x1>;
	remote-endpoint = <&{/rkispp-vir1/port/endpoint@0}>;
	phandle = <0x92>;
};

/* /rkisp-vir2 */
rkisp-vir2 {
	compatible = "rockchip,rv1126-rkisp-vir";
	rockchip,hw = <0x8a>;
	status = "disabled";
	phandle = <0x113>;
	ports {
		#address-cells = <0x1>;
		#size-cells = "", "", "", "";
		port@1 {
			reg = <0x1>;
			#address-cells = <0x1>;
			#size-cells = "", "", "", "";
			endpoint@1 {
				reg = <0x1>;
				remote-endpoint = <&{/rkispp-vir2/port/endpoint@0}>;
				phandle = <0x93>;
			};
		};
	};
};

/* /rkisp-vir2/ports */
ports {
	#address-cells = <0x1>;
	#size-cells = "", "", "", "";
	port@1 {
		reg = <0x1>;
		#address-cells = <0x1>;
		#size-cells = "", "", "", "";
		endpoint@1 {
			reg = <0x1>;
			remote-endpoint = <&{/rkispp-vir2/port/endpoint@0}>;
			phandle = <0x93>;
		};
	};
};

/* /rkisp-vir2/ports/port@1 */
port@1 {
	reg = <0x1>;
	#address-cells = <0x1>;
	#size-cells = "", "", "", "";
	endpoint@1 {
		reg = <0x1>;
		remote-endpoint = <&{/rkispp-vir2/port/endpoint@0}>;
		phandle = <0x93>;
	};
};

/* /rkisp-vir2/ports/port@1/endpoint@1 */
endpoint@1 {
	reg = <0x1>;
	remote-endpoint = <&{/rkispp-vir2/port/endpoint@0}>;
	phandle = <0x93>;
};

/* /rkispp@ffb60000 */
rkispp@ffb60000 {
	compatible = "rockchip,rv1126-rkispp";
	reg = <0xffb60000 0x20000>;
	interrupts = <0x0 0x3f 0x4 0x0 0x40 0x4>;
	interrupt-names = "ispp_irq", "fec_irq";
	clocks = <0x2 0xba 0x2 0xe1 0x2 0x6b>;  /* 0x2->&{/clock-controller@ff490000}, 0xba->&{/pinctrl/pcfg-output-low}, 0x2->&{/clock-controller@ff490000}, 0xe1->&{/pwm@ff430000}, 0x2->&{/clock-controller@ff490000}, 0x6b->&{/otp@ff5c0000/tsadc-trim-base@27} */
	clock-names = "aclk_ispp", "hclk_ispp", "clk_ispp";
	assigned-clocks = <0x2 0xba 0x2 0xe1 0x2 0x6b>;  /* 0x2->&{/clock-controller@ff490000}, 0xba->&{/pinctrl/pcfg-output-low}, 0x2->&{/clock-controller@ff490000}, 0xe1->&{/pwm@ff430000}, 0x2->&{/clock-controller@ff490000}, 0x6b->&{/otp@ff5c0000/tsadc-trim-base@27} */
	assigned-clock-rates = <0x1dcd6500 0xee6b280 0x17d78400>;
	power-domains = <0x4d 0xb>;  /* 0x4d->&{/power-management@ff3e0000/power-controller}, 0xb->&{/cpus/cpu@f01} */
	iommus = <&{/iommu@ffb60e00}>;
	rockchip,restart-monitor-en;
	status = "okay";
	phandle = <0x90>;
};

/* /iommu@ffb60e00 */
iommu@ffb60e00 {
	compatible = "rockchip,iommu";
	reg = <0xffb60e00 0x40 0xffb60e40 0x40 0xffb60f00 0x40>;
	interrupts = <0x0 0x41 0x4 0x0 0x42 0x4 0x0 0x43 0x4>;
	interrupt-names = "ispp_mmu0_r", "ispp_mmu0_w", "ispp_mmu1";
	clocks = <0x2 0xba 0x2 0xe1>;  /* 0x2->&{/clock-controller@ff490000}, 0xba->&{/pinctrl/pcfg-output-low}, 0x2->&{/clock-controller@ff490000}, 0xe1->&{/pwm@ff430000} */
	clock-names = "aclk", "iface";
	power-domains = <0x4d 0xb>;  /* 0x4d->&{/power-management@ff3e0000/power-controller}, 0xb->&{/cpus/cpu@f01} */
	#iommu-cells = "", "", "", "";
	rockchip,disable-mmu-reset;
	status = "okay";
	phandle = <0x8f>;
};

/* /rkispp-vir0 */
rkispp-vir0 {
	compatible = "rockchip,rv1126-rkispp-vir";
	rockchip,hw = <0x90>;
	status = "okay";
	phandle = <0x114>;
	port {
		#address-cells = <0x1>;
		#size-cells = "", "", "", "";
		endpoint@0 {
			reg = "", "", "", "";
			remote-endpoint = <&{/rkisp-vir0/ports/port@1/endpoint@1}>;
			phandle = <0x8b>;
		};
	};
};

/* /rkispp-vir0/port */
port {
	#address-cells = <0x1>;
	#size-cells = "", "", "", "";
	endpoint@0 {
		reg = "", "", "", "";
		remote-endpoint = <&{/rkisp-vir0/ports/port@1/endpoint@1}>;
		phandle = <0x8b>;
	};
};

/* /rkispp-vir0/port/endpoint@0 */
endpoint@0 {
	reg = "", "", "", "";
	remote-endpoint = <&{/rkisp-vir0/ports/port@1/endpoint@1}>;
	phandle = <0x8b>;
};

/* /rkispp-vir1 */
rkispp-vir1 {
	compatible = "rockchip,rv1126-rkispp-vir";
	rockchip,hw = <0x90>;
	status = "disabled";
	phandle = <0x115>;
	port {
		#address-cells = <0x1>;
		#size-cells = "", "", "", "";
		endpoint@0 {
			reg = "", "", "", "";
			remote-endpoint = <&{/rkisp-vir1/ports/port@1/endpoint@1}>;
			phandle = <0x8d>;
		};
	};
};

/* /rkispp-vir1/port */
port {
	#address-cells = <0x1>;
	#size-cells = "", "", "", "";
	endpoint@0 {
		reg = "", "", "", "";
		remote-endpoint = <&{/rkisp-vir1/ports/port@1/endpoint@1}>;
		phandle = <0x8d>;
	};
};

/* /rkispp-vir1/port/endpoint@0 */
endpoint@0 {
	reg = "", "", "", "";
	remote-endpoint = <&{/rkisp-vir1/ports/port@1/endpoint@1}>;
	phandle = <0x8d>;
};

/* /rkispp-vir2 */
rkispp-vir2 {
	compatible = "rockchip,rv1126-rkispp-vir";
	rockchip,hw = <0x90>;
	status = "disabled";
	phandle = <0x116>;
	port {
		#address-cells = <0x1>;
		#size-cells = "", "", "", "";
		endpoint@0 {
			reg = "", "", "", "";
			remote-endpoint = <&{/rkisp-vir2/ports/port@1/endpoint@1}>;
			phandle = <0x8e>;
		};
	};
};

/* /rkispp-vir2/port */
port {
	#address-cells = <0x1>;
	#size-cells = "", "", "", "";
	endpoint@0 {
		reg = "", "", "", "";
		remote-endpoint = <&{/rkisp-vir2/ports/port@1/endpoint@1}>;
		phandle = <0x8e>;
	};
};

/* /rkispp-vir2/port/endpoint@0 */
endpoint@0 {
	reg = "", "", "", "";
	remote-endpoint = <&{/rkisp-vir2/ports/port@1/endpoint@1}>;
	phandle = <0x8e>;
};

/* /__symbols__ */
__symbols__ {
	ddr_timing = "/ddr_timing";
	cpu0 = "/cpus/cpu@f00";
	cpu1 = "/cpus/cpu@f01";
	cpu2 = "/cpus/cpu@f02";
	cpu3 = "/cpus/cpu@f03";
	CPU_SLEEP = "/cpus/idle-states/cpu-sleep";
	cpu0_opp_table = "/cpu0-opp-table";
	bus_soc = "/bus-soc";
	display_subsystem = "/display-subsystem";
	route_dsi = "/display-subsystem/route/route-dsi";
	route_rgb = "/display-subsystem/route/route-rgb";
	fiq_debugger = "/fiq-debugger";
	optee = "/firmware/optee";
	mpp_srv = "/mpp-srv";
	drm_logo = "/reserved-memory/drm-logo@00000000";
	isp_reserved = "/reserved-memory/isp";
	ramoops = "/reserved-memory/ramoops@8000000";
	rkcif_dvp = "/rkcif_dvp";
	rkcif_dvp_sditf = "/rkcif_dvp_sditf";
	rkcif_lite_mipi_lvds = "/rkcif_lite_mipi_lvds";
	rkcif_lite_sditf = "/rkcif_lite_sditf";
	rkcif_mipi_lvds = "/rkcif_mipi_lvds";
	cif_mipi_in = "/rkcif_mipi_lvds/port/endpoint";
	rkcif_mipi_lvds_sditf = "/rkcif_mipi_lvds_sditf";
	lvds_sditf = "/rkcif_mipi_lvds_sditf/port/endpoint";
	rockchip_suspend = "/rockchip-suspend";
	rockchip_system_monitor = "/rockchip-system-monitor";
	thermal_zones = "/thermal-zones";
	cpu_thermal = "/thermal-zones/cpu-thermal";
	threshold = "/thermal-zones/cpu-thermal/trips/trip-point-0";
	target = "/thermal-zones/cpu-thermal/trips/trip-point-1";
	soc_crit = "/thermal-zones/cpu-thermal/trips/soc-crit";
	npu_thermal = "/thermal-zones/npu-thermal";
	xin24m = "/oscillator";
	dummy_cpll = "/dummy_cpll";
	gmac_clkin_m0 = "/external-gmac-clockm0";
	gmac_clkini_m1 = "/external-gmac-clockm1";
	grf = "/syscon@fe000000";
	rgb = "/syscon@fe000000/rgb";
	rgb_in_vop = "/syscon@fe000000/rgb/ports/port@0/endpoint@0";
	pmugrf = "/syscon@fe020000";
	pmu_io_domains = "/syscon@fe020000/io-domains";
	qos_usb_host = "/qos@fe810000";
	qos_usb_otg = "/qos@fe810080";
	qos_npu = "/qos@fe850000";
	qos_emmc = "/qos@fe860000";
	qos_nandc = "/qos@fe860080";
	qos_sfc = "/qos@fe860200";
	qos_sdio = "/qos@fe86c000";
	qos_vepu_rd0 = "/qos@fe870000";
	qos_vepu_rd1 = "/qos@fe870080";
	qos_vepu_wr = "/qos@fe870100";
	qos_ispp_m0 = "/qos@fe880000";
	qos_ispp_m1 = "/qos@fe880080";
	qos_isp = "/qos@fe890000";
	qos_cif_lite = "/qos@fe890080";
	qos_cif = "/qos@fe890100";
	qos_iep = "/qos@fe8a0000";
	qos_rga_rd = "/qos@fe8a0080";
	qos_rga_wr = "/qos@fe8a0100";
	qos_vop = "/qos@fe8a0180";
	qos_vdpu = "/qos@fe8b0000";
	qos_jpeg = "/qos@fe8c0000";
	qos_crypto = "/qos@fe8d0000";
	gic = "/interrupt-controller@feff0000";
	pmu = "/power-management@ff3e0000";
	power = "/power-management@ff3e0000/power-controller";
	i2c0 = "/i2c@ff3f0000";
	es7202 = "/i2c@ff3f0000/es7202@30";
	i2c2 = "/i2c@ff400000";
	dmac = "/amba/dma-controller@ff4e0000";
	uart1 = "/serial@ff410000";
	pwm0 = "/pwm@ff430000";
	pwm1 = "/pwm@ff430010";
	pwm2 = "/pwm@ff430020";
	pwm3 = "/pwm@ff430030";
	pwm4 = "/pwm@ff440000";
	pwm5 = "/pwm@ff440010";
	pwm6 = "/pwm@ff440020";
	pwm7 = "/pwm@ff440030";
	spi0 = "/spi@ff450000";
	pmucru = "/clock-controller@ff480000";
	cru = "/clock-controller@ff490000";
	csi_dphy0 = "/csi-dphy@ff4b0000";
	mipi_in_ucam0 = "/csi-dphy@ff4b0000/ports/port@0/endpoint@1";
	csidphy0_out = "/csi-dphy@ff4b0000/ports/port@1/endpoint@0";
	csi_dphy1 = "/csi-dphy@ff4b8000";
	u2phy0 = "/usb2-phy@ff4c0000";
	u2phy_otg = "/usb2-phy@ff4c0000/otg-port";
	u2phy1 = "/usb2-phy@ff4c8000";
	u2phy_host = "/usb2-phy@ff4c8000/host-port";
	mipi_dphy = "/mipi-dphy@ff4d0000";
	rng = "/rng@ff500400";
	crypto = "/crypto@ff500000";
	i2c1 = "/i2c@ff510000";
	sc5338 = "/i2c@ff510000/sc5338@30";
	ucam_out0 = "/i2c@ff510000/sc5338@30/port/endpoint";
	sc530ai = "/i2c@ff510000/sc530ai@30";
	sc401ai = "/i2c@ff510000/sc401ai@30";
	i2c3 = "/i2c@ff520000";
	i2c4 = "/i2c@ff530000";
	pcf8563 = "/i2c@ff530000/pcf8563@51";
	i2c5 = "/i2c@ff540000";
	pwm8 = "/pwm@ff550000";
	pwm9 = "/pwm@ff550010";
	pwm10 = "/pwm@ff550020";
	pwm11 = "/pwm@ff550030";
	uart0 = "/serial@ff560000";
	uart2 = "/serial@ff570000";
	uart3 = "/serial@ff580000";
	uart4 = "/serial@ff590000";
	uart5 = "/serial@ff5a0000";
	spi1 = "/spi@ff5b0000";
	otp = "/otp@ff5c0000";
	otp_cpu_code = "/otp@ff5c0000/cpu-code@2";
	otp_id = "/otp@ff5c0000/id@7";
	cpu_leakage = "/otp@ff5c0000/cpu-leakage@17";
	logic_leakage = "/otp@ff5c0000/logic-leakage@18";
	npu_leakage = "/otp@ff5c0000/npu-leakage@19";
	venc_leakage = "/otp@ff5c0000/venc-leakage@1a";
	cpu_performance = "/otp@ff5c0000/cpu-performance@1e";
	npu_performance = "/otp@ff5c0000/npu-performance@1f";
	venc_performance = "/otp@ff5c0000/venc-performance@1f";
	cpu_tsadc_trim_l = "/otp@ff5c0000/cpu-tsadc-trim-l@23";
	cpu_tsadc_trim_h = "/otp@ff5c0000/cpu-tsadc-trim-h@24";
	npu_tsadc_trim_l = "/otp@ff5c0000/npu-tsadc-trim-l@25";
	npu_tsadc_trim_h = "/otp@ff5c0000/npu-tsadc-trim-h@26";
	tsadc_trim_base = "/otp@ff5c0000/tsadc-trim-base@27";
	saradc = "/saradc@ff5e0000";
	cpu_tsadc = "/tsadc@ff5f0000";
	npu_tsadc = "/tsadc@ff5f8000";
	dcf = "/dcf@ff600000";
	can = "/can@ff610000";
	rktimer = "/rktimer@ff660000";
	wdt = "/watchdog@ff680000";
	mailbox = "/mailbox@ff6a0000";
	hw_decompress = "/decompress@ff6c0000";
	i2s0_8ch = "/i2s@ff800000";
	i2s1_2ch = "/i2s@ff810000";
	i2s2_2ch = "/i2s@ff820000";
	pdm = "/pdm@ff830000";
	audpwm = "/audpwm@ff840000";
	rkacdc_dig = "/codec-digital@ff850000";
	dfi = "/dfi@ff9c0000";
	dmc = "/dmc";
	dmc_opp_table = "/dmc-opp-table";
	dmcdbg = "/dmcdbg";
	rkcif = "/rkcif@ffae0000";
	rkcif_mmu = "/iommu@ffae0800";
	rkcif_lite = "/rkcif_lite@ffae8000";
	rkcif_lite_mmu = "/iommu@ffae8800";
	rk_rga = "/rk_rga@ffaf0000";
	vop = "/vop@ffb00000";
	vop_out = "/vop@ffb00000/port";
	vop_out_rgb = "/vop@ffb00000/port/endpoint@0";
	vop_out_dsi = "/vop@ffb00000/port/endpoint@1";
	vop_mmu = "/iommu@ffb00f00";
	mipi_csi2 = "/mipi-csi2@ffb10000";
	mipi_csi2_input = "/mipi-csi2@ffb10000/ports/port@0/endpoint@1";
	mipi_csi2_output = "/mipi-csi2@ffb10000/ports/port@1/endpoint@0";
	iep = "/iep@ffb20000";
	iep_mmu = "/iommu@ffb20800";
	dsi = "/dsi@ffb30000";
	dsi_in_vop = "/dsi@ffb30000/ports/port/endpoint";
	rkisp = "/rkisp@ffb50000";
	rkisp_mmu = "/iommu@ffb51a00";
	rkisp_vir0 = "/rkisp-vir0";
	isp0_out = "/rkisp-vir0/ports/port@1/endpoint@1";
	isp_in = "/rkisp-vir0/ports/port@0/endpoint@0";
	rkisp_vir1 = "/rkisp-vir1";
	isp1_out = "/rkisp-vir1/ports/port@1/endpoint@1";
	rkisp_vir2 = "/rkisp-vir2";
	isp2_out = "/rkisp-vir2/ports/port@1/endpoint@1";
	rkispp = "/rkispp@ffb60000";
	rkispp_mmu = "/iommu@ffb60e00";
	rkispp_vir0 = "/rkispp-vir0";
	ispp0_in = "/rkispp-vir0/port/endpoint@0";
	rkispp_vir1 = "/rkispp-vir1";
	ispp1_in = "/rkispp-vir1/port/endpoint@0";
	rkispp_vir2 = "/rkispp-vir2";
	ispp2_in = "/rkispp-vir2/port/endpoint@0";
	rkvdec = "/rkvdec@ffb80000";
	rkvdec_mmu = "/iommu@ffb80480";
	vepu = "/vepu@ffb90000";
	vdpu = "/vdpu@ffb90400";
	vpu_mmu = "/iommu@ffb90800";
	rkvenc = "/rkvenc@ffbb0000";
	rkvenc_opp_table = "/rkvenc-opp-table";
	rkvenc_mmu = "/iommu@ffbb0f00";
	gmac = "/ethernet@ffc40000";
	mdio = "/ethernet@ffc40000/mdio";
	phy = "/ethernet@ffc40000/mdio/phy@0";
	stmmac_axi_setup = "/ethernet@ffc40000/stmmac-axi-config";
	mtl_rx_setup = "/ethernet@ffc40000/rx-queues-config";
	mtl_tx_setup = "/ethernet@ffc40000/tx-queues-config";
	emmc = "/dwmmc@ffc50000";
	sdmmc = "/dwmmc@ffc60000";
	sdio = "/dwmmc@ffc70000";
	nandc = "/nandc@ffc80000";
	sfc = "/sfc@ffc90000";
	npu = "/npu@ffbc0000";
	npu_opp_table = "/npu-opp-table";
	usbdrd = "/usb0";
	usbdrd_dwc3 = "/usb0/dwc3@ffd00000";
	usb_host0_ehci = "/usb@ffe00000";
	usb_host0_ohci = "/usb@ffe10000";
	pinctrl = "/pinctrl";
	gpio0 = "/pinctrl/gpio0@ff460000";
	gpio1 = "/pinctrl/gpio1@ff620000";
	gpio2 = "/pinctrl/gpio2@ff630000";
	gpio3 = "/pinctrl/gpio3@ff640000";
	gpio4 = "/pinctrl/gpio4@ff650000";
	pcfg_pull_up = "/pinctrl/pcfg-pull-up";
	pcfg_pull_down = "/pinctrl/pcfg-pull-down";
	pcfg_pull_none = "/pinctrl/pcfg-pull-none";
	pcfg_pull_none_drv_level_0 = "/pinctrl/pcfg-pull-none-drv-level-0";
	pcfg_pull_none_drv_level_2 = "/pinctrl/pcfg-pull-none-drv-level-2";
	pcfg_pull_none_drv_level_3 = "/pinctrl/pcfg-pull-none-drv-level-3";
	pcfg_pull_none_drv_level_8 = "/pinctrl/pcfg-pull-none-drv-level-8";
	pcfg_pull_up_drv_level_0 = "/pinctrl/pcfg-pull-up-drv-level-0";
	pcfg_pull_up_drv_level_1 = "/pinctrl/pcfg-pull-up-drv-level-1";
	pcfg_pull_up_drv_level_2 = "/pinctrl/pcfg-pull-up-drv-level-2";
	pcfg_pull_none_drv_level_0_smt = "/pinctrl/pcfg-pull-none-drv-level-0-smt";
	pcfg_output_low = "/pinctrl/pcfg-output-low";
	auddsm_pins = "/pinctrl/auddsm/auddsm-pins";
	audpwmm0_pins = "/pinctrl/audpwm/audpwmm0-pins";
	emmc_bus8 = "/pinctrl/emmc/emmc-bus8";
	emmc_clk = "/pinctrl/emmc/emmc-clk";
	emmc_cmd = "/pinctrl/emmc/emmc-cmd";
	i2c0_xfer = "/pinctrl/i2c0/i2c0-xfer";
	i2c1_xfer = "/pinctrl/i2c1/i2c1-xfer";
	i2c2_xfer = "/pinctrl/i2c2/i2c2-xfer";
	i2c3m0_xfer = "/pinctrl/i2c3/i2c3m0-xfer";
	i2c4m0_xfer = "/pinctrl/i2c4/i2c4m0-xfer";
	i2c5m0_xfer = "/pinctrl/i2c5/i2c5m0-xfer";
	i2s1m0_lrck = "/pinctrl/i2s1/i2s1m0-lrck";
	i2s1m0_sclk = "/pinctrl/i2s1/i2s1m0-sclk";
	i2s1m0_sdi = "/pinctrl/i2s1/i2s1m0-sdi";
	i2s1m0_sdo = "/pinctrl/i2s1/i2s1m0-sdo";
	i2s2m0_lrck = "/pinctrl/i2s2/i2s2m0-lrck";
	i2s2m0_sclk = "/pinctrl/i2s2/i2s2m0-sclk";
	i2s2m0_sdi = "/pinctrl/i2s2/i2s2m0-sdi";
	i2s2m0_sdo = "/pinctrl/i2s2/i2s2m0-sdo";
	mipicsi_clk0 = "/pinctrl/mipicsi/mipicsi-clk0";
	pdmm0_clk = "/pinctrl/pdm/pdmm0-clk";
	pdmm0_sdi0 = "/pinctrl/pdm/pdmm0-sdi0";
	pwm2m0_pins = "/pinctrl/pwm2/pwm2m0-pins";
	pwm3m0_pins = "/pinctrl/pwm3/pwm3m0-pins";
	pwm4m0_pins = "/pinctrl/pwm4/pwm4m0-pins";
	pwm5m0_pins = "/pinctrl/pwm5/pwm5m0-pins";
	pwm6m0_pins = "/pinctrl/pwm6/pwm6m0-pins";
	pwm7m0_pins = "/pinctrl/pwm7/pwm7m0-pins";
	pwm8m1_pins = "/pinctrl/pwm8/pwm8m1-pins";
	pwm9m1_pins = "/pinctrl/pwm9/pwm9m1-pins";
	pwm10m0_pins = "/pinctrl/pwm10/pwm10m0-pins";
	pwm11m0_pins = "/pinctrl/pwm11/pwm11m0-pins";
	sdio_bus4 = "/pinctrl/sdio/sdio-bus4";
	sdio_clk = "/pinctrl/sdio/sdio-clk";
	sdio_cmd = "/pinctrl/sdio/sdio-cmd";
	sdmmc0_bus4 = "/pinctrl/sdmmc0/sdmmc0-bus4";
	sdmmc0_clk = "/pinctrl/sdmmc0/sdmmc0-clk";
	sdmmc0_cmd = "/pinctrl/sdmmc0/sdmmc0-cmd";
	sdmmc0_det = "/pinctrl/sdmmc0/sdmmc0-det";
	spi1m0_pins = "/pinctrl/spi1/spi1m0-pins";
	spi1m0_cs0 = "/pinctrl/spi1/spi1m0-cs0";
	spi1m0_cs1 = "/pinctrl/spi1/spi1m0-cs1";
	tsadcm0_shut = "/pinctrl/tsadc/tsadcm0-shut";
	tsadc_shutorg = "/pinctrl/tsadc/tsadc-shutorg";
	uart0_xfer = "/pinctrl/uart0/uart0-xfer";
	uart0_ctsn = "/pinctrl/uart0/uart0-ctsn";
	uart0_rtsn = "/pinctrl/uart0/uart0-rtsn";
	uart1m0_xfer = "/pinctrl/uart1/uart1m0-xfer";
	uart1m0_ctsn = "/pinctrl/uart1/uart1m0-ctsn";
	uart1m0_rtsn = "/pinctrl/uart1/uart1m0-rtsn";
	uart2m1_xfer = "/pinctrl/uart2/uart2m1-xfer";
	uart3m2_xfer = "/pinctrl/uart3/uart3m2-xfer";
	uart4m0_xfer = "/pinctrl/uart4/uart4m0-xfer";
	uart4m0_ctsn = "/pinctrl/uart4/uart4m0-ctsn";
	uart4m0_rtsn = "/pinctrl/uart4/uart4m0-rtsn";
	uart5m0_xfer = "/pinctrl/uart5/uart5m0-xfer";
	uart5m0_ctsn = "/pinctrl/uart5/uart5m0-ctsn";
	uart5m0_rtsn = "/pinctrl/uart5/uart5m0-rtsn";
	pwm0m0_pins_pull_down = "/pinctrl/pwm-pull-down/pwm0m0-pins";
	pwm1m0_pins_pull_down = "/pinctrl/pwm-pull-down/pwm1m0-pins";
	spi1m0_pins_hs = "/pinctrl/spi1-hs/spi1m0-pins";
	gmac_clk_m0_pins = "/pinctrl/gmac_clk/gmac-clk-m0-pins";
	rmiim0_miim = "/pinctrl/rmii/rmiim0-miim";
	rmiim0_bus2 = "/pinctrl/rmii/rmiim0-bus2";
	key_reset = "/pinctrl/key/key-reset";
	sdmmc_pwr = "/pinctrl/sdmmc-pwr/sdmmc-pwr";
	vcc5v0_sys = "/vccsys";
	vcc_1v8 = "/vcc-1v8";
	vcc_dvdd = "/vcc-dvdd";
	vcc3v3_sys = "/vcc33sys";
	vcc2v8_sys = "/vcc28sys";
	vdd_arm_logic_npu_vepu_fixed = "/vdd-arm-logic-npu-vepu-fixed";
	rkacdc_dig_sound = "/rkacdc-dig-sound";
	sndcpu = "/rkacdc-dig-sound/simple-audio-card,cpu";
	sndcodec = "/rkacdc-dig-sound/simple-audio-card,codec";
	es7202_sound = "/es7202-sound";
};
